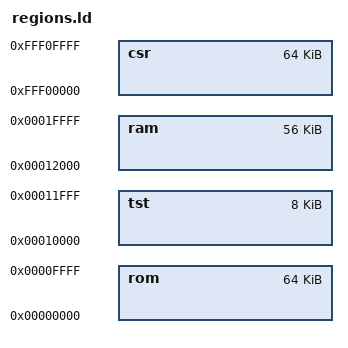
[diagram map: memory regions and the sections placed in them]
MEMORY {
	rom : ORIGIN = 0x00000000, LENGTH = 0x00010000
   tst : ORIGIN = 0x00010000, LENGTH = 0x00002000
	ram : ORIGIN = 0x00012000, LENGTH = 0x0000E000
	csr : ORIGIN = 0xFFF00000, LENGTH = 0x00010000
}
